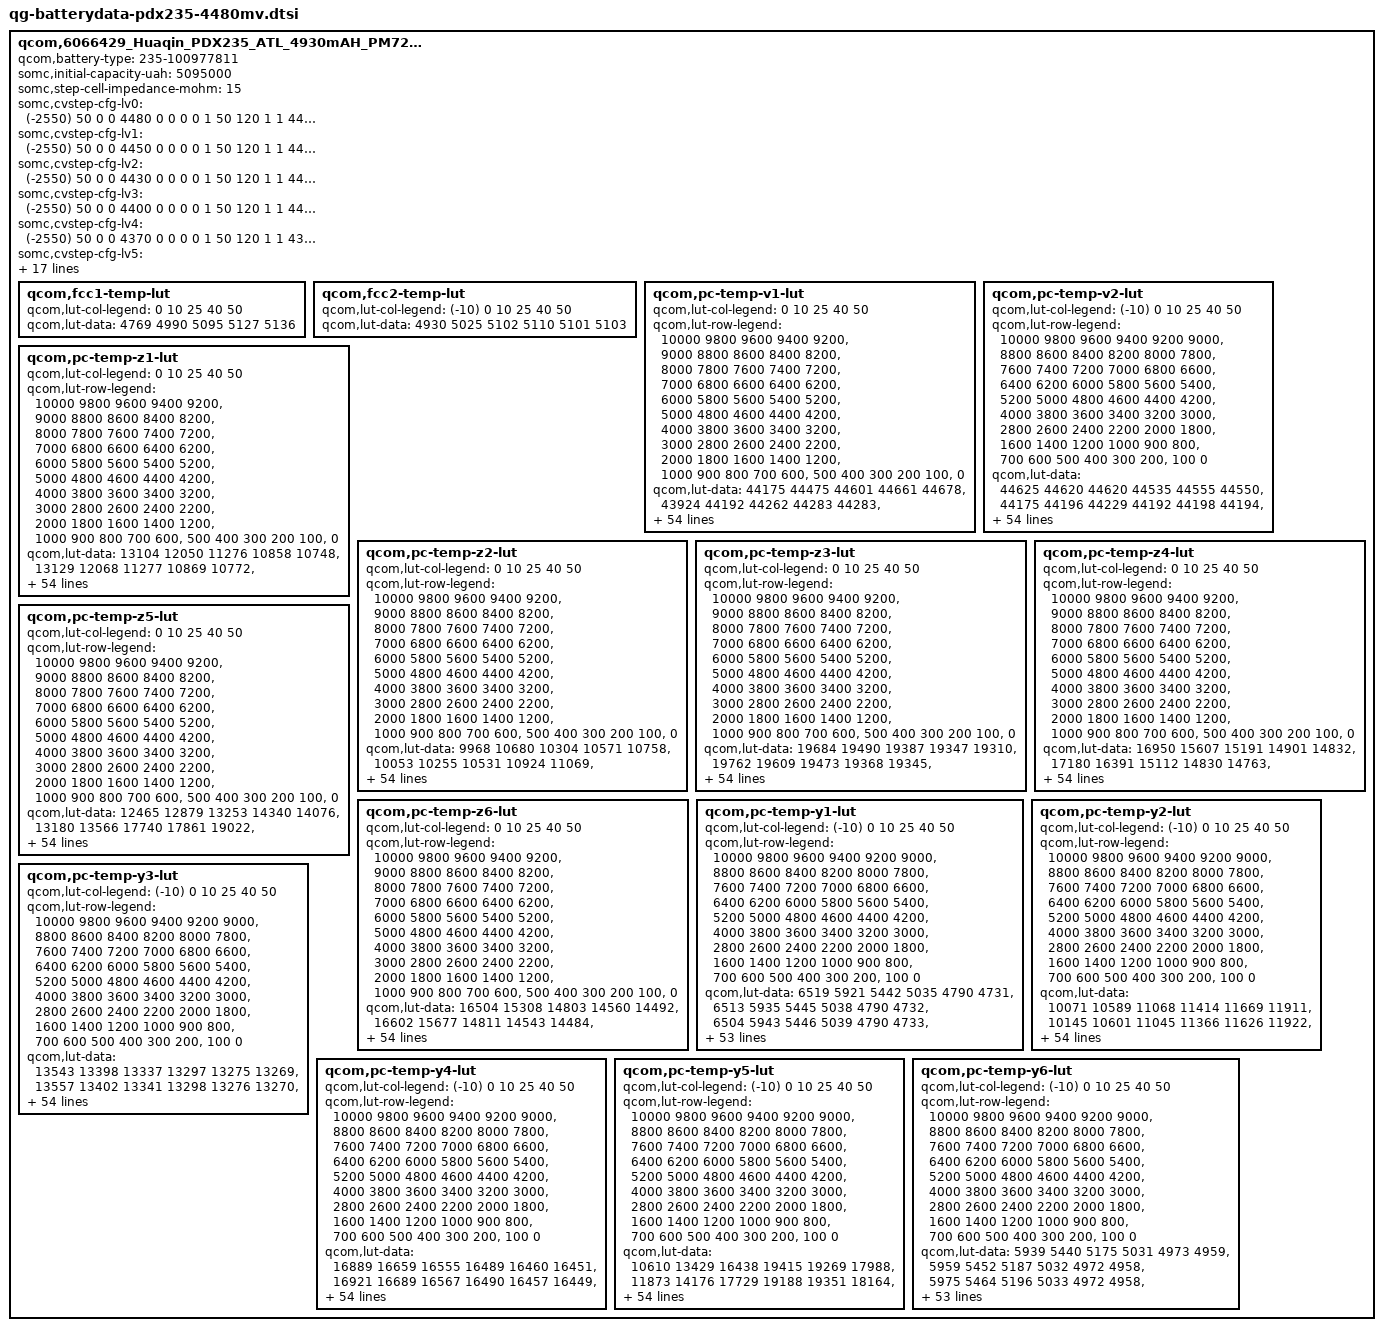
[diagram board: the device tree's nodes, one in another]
/* Copyright (c) 2018, The Linux Foundation. All rights reserved.
 *
 * This program is free software; you can redistribute it and/or modify
 * it under the terms of the GNU General Public License version 2 and
 * only version 2 as published by the Free Software Foundation.
 *
 * This program is distributed in the hope that it will be useful,
 * but WITHOUT ANY WARRANTY; without even the implied warranty of
 * MERCHANTABILITY or FITNESS FOR A PARTICULAR PURPOSE.  See the
 * GNU General Public License for more details.
 */

qcom,6066429_Huaqin_PDX235_ATL_4930mAH_PM7250B {
	qcom,battery-type = "235-100977811";
	somc,initial-capacity-uah = <5095000>;
	somc,step-cell-impedance-mohm = <15>;
	somc,cvstep-cfg-lv0 = <
		(-2550) 50 0 0 4480    0    0    0   0 1
		   50  120 1 1 4400  950  738  950   0 2
		   50  120 1 2 4480  700    0    0 246 2
		  120  150 2 1 4150 2450 1968 2450   0 3
		  120  150 2 2 4250 1950 1476 1950   0 3
		  120  150 2 3 4350 1450  984 1450   0 3
		  120  150 2 4 4480  950    0    0 246 3
		  150  200 3 1 4150 2950 2460 2950   0 3
		  150  200 3 2 4250 2450 1968 2450   0 3
		  150  200 3 3 4350 1950 1476 1950   0 3
		  150  200 3 4 4480 1450    0    0 246 3
		  200  350 4 1 4250 5000 3788 5000   0 3
		  200  350 4 2 4300 3750 2460 3750   0 3
		  200  350 4 3 4400 2450 1722 2450   0 3
		  200  350 4 4 4480 1700    0    0 246 3
		  350  450 5 1 4250 5000 3788 5000   0 3
		  350  450 5 2 4300 3750 2460 3750   0 3
		  350  450 5 3 4400 2450 1722 2450   0 3
		  350  450 5 4 4480 1700    0    0 394 3
		  450  550 6 1 4200 1450    0    0 394 4
		  550 2550 7 1 4200    0    0    0   0 5
		    0    0 0 0    0    0    0    0   0 0
	>;

	somc,cvstep-cfg-lv1 = <
		(-2550) 50 0 0 4450    0    0    0   0 1
		   50  120 1 1 4400  950  738  950   0 2
		   50  120 1 2 4450  700    0    0 246 2
		  120  150 2 1 4150 2450 1968 2450   0 3
		  120  150 2 2 4250 1950 1476 1950   0 3
		  120  150 2 3 4350 1450  984 1450   0 3
		  120  150 2 4 4450  950    0    0 246 3
		  150  200 3 1 4150 2700 2214 2700   0 3
		  150  200 3 2 4250 2200 1968 2200   0 3
		  150  200 3 3 4350 1950 1476 1950   0 3
		  150  200 3 4 4450 1450    0    0 246 3
		  200  350 4 1 4200 4650 3444 4650   0 3
		  200  350 4 2 4250 3400 2214 3400   0 3
		  200  350 4 3 4350 2200 1476 2200   0 3
		  200  350 4 4 4450 1450    0    0 246 3
		  350  450 5 1 4200 4650 3444 4650   0 3
		  350  450 5 2 4250 3400 2214 3400   0 3
		  350  450 5 3 4350 2200 1476 2200   0 3
		  350  450 5 4 4450 1450    0    0 394 3
		  450  550 6 1 4200 1450    0    0 394 4
		  550 2550 7 1 4200    0    0    0   0 5
		    0    0 0 0    0    0    0    0   0 0
	>;

	somc,cvstep-cfg-lv2 = <
		(-2550) 50 0 0 4430    0    0    0   0 1
		   50  120 1 1 4400  950  738  950   0 2
		   50  120 1 2 4430  700    0    0 246 2
		  120  150 2 1 4150 2200 1722 2200   0 3
		  120  150 2 2 4250 1700 1476 1700   0 3
		  120  150 2 3 4350 1450  984 1450   0 3
		  120  150 2 4 4430  950    0    0 246 3
		  150  200 3 1 4150 2700 2214 2700   0 3
		  150  200 3 2 4250 2200 1968 2200   0 3
		  150  200 3 3 4350 1950 1230 1950   0 3
		  150  200 3 4 4430 1200    0    0 246 3
		  200  350 4 1 4200 4400 3444 4400   0 3
		  200  350 4 2 4250 3400 2214 3400   0 3
		  200  350 4 3 4350 2200 1476 2200   0 3
		  200  350 4 4 4430 1450    0    0 246 3
		  350  450 5 1 4200 4400 3444 4400   0 3
		  350  450 5 2 4250 3400 2214 3400   0 3
		  350  450 5 3 4350 2200 1476 2200   0 3
		  350  450 5 4 4430 1450    0    0 394 3
		  450  550 6 1 4200 1450    0    0 394 4
		  550 2550 7 1 4200    0    0    0   0 5
		    0    0 0 0    0    0    0    0   0 0
	>;

	somc,cvstep-cfg-lv3 = <
		(-2550) 50 0 0 4400    0    0    0   0 1
		   50  120 1 1 4400  950    0    0 246 2
		  120  150 2 1 4150 1950 1476 1950   0 3
		  120  150 2 2 4250 1450  984 1450   0 3
		  120  150 2 3 4400  950    0    0 246 3
		  150  200 3 1 4100 2450 1968 2450   0 3
		  150  200 3 2 4200 1950 1722 1950   0 3
		  150  200 3 3 4300 1700  984 1700   0 3
		  150  200 3 4 4400  950    0    0 246 3
		  200  350 4 1 4150 3900 2952 3900   0 3
		  200  350 4 2 4200 2950 1722 2950   0 3
		  200  350 4 3 4300 1700 1230 1700   0 3
		  200  350 4 4 4400 1200    0    0 246 3
		  350  450 5 1 4150 3900 2952 3900   0 3
		  350  450 5 2 4200 2950 1722 2950   0 3
		  350  450 5 3 4300 1700 1230 1700   0 3
		  350  450 5 4 4400 1200    0    0 394 3
		  450  550 6 1 4200 1450    0    0 394 4
		  550 2550 7 1 4200    0    0    0   0 5
		    0    0 0 0    0    0    0    0   0 0
	>;

	somc,cvstep-cfg-lv4 = <
		(-2550) 50 0 0 4370    0    0    0   0 1
		   50  120 1 1 4370  950    0    0 246 2
		  120  150 2 1 4150 1950 1476 1950   0 3
		  120  150 2 2 4250 1450  984 1450   0 3
		  120  150 2 3 4370  950    0    0 246 3
		  150  200 3 1 4100 2450 1968 2450   0 3
		  150  200 3 2 4200 1950 1722 1950   0 3
		  150  200 3 3 4300 1700  984 1700   0 3
		  150  200 3 4 4370  950    0    0 246 3
		  200  350 4 1 4150 3900 2952 3900   0 3
		  200  350 4 2 4200 2950 1722 2950   0 3
		  200  350 4 3 4300 1700 1230 1700   0 3
		  200  350 4 4 4370 1200    0    0 246 3
		  350  450 5 1 4150 3900 2952 3900   0 3
		  350  450 5 2 4200 2950 1722 2950   0 3
		  350  450 5 3 4300 1700 1230 1700   0 3
		  350  450 5 4 4370 1200    0    0 394 3
		  450  550 6 1 4200 1450    0    0 394 4
		  550 2550 7 1 4200    0    0    0   0 5
		    0    0 0 0    0    0    0    0   0 0
	>;

	somc,cvstep-cfg-lv5 = <
		(-2550) 50 0 0 4350    0    0    0   0 1
		   50  120 1 1 4350  950    0    0 246 2
		  120  150 2 1 4150 1950 1476 1950   0 3
		  120  150 2 2 4250 1450  984 1450   0 3
		  120  150 2 3 4350  950    0    0 246 3
		  150  200 3 1 4100 2450 1968 2450   0 3
		  150  200 3 2 4200 1950 1722 1950   0 3
		  150  200 3 3 4300 1700  984 1700   0 3
		  150  200 3 4 4350  950    0    0 246 3
		  200  350 4 1 4150 3900 2952 3900   0 3
		  200  350 4 2 4200 2950 1722 2950   0 3
		  200  350 4 3 4300 1700 1230 1700   0 3
		  200  350 4 4 4350 1200    0    0 246 3
		  350  450 5 1 4150 3900 2952 3900   0 3
		  350  450 5 2 4200 2950 1722 2950   0 3
		  350  450 5 3 4300 1700 1230 1700   0 3
		  350  450 5 4 4350 1200    0    0 394 3
		  450  550 6 1 4200 1450    0    0 394 4
		  550 2550 7 1 4200    0    0    0   0 5
		    0    0 0 0    0    0    0    0   0 0
	>;

    /* 6066429_Huaqin_PDX235_ATL_4930mAH_PM7250B_averaged_MasterSlave_Aug29th2022 */
    qcom,max-voltage-uv = <4480000>;
    qcom,fg-cc-cv-threshold-uv = <4470000>;
    qcom,fastchg-current-ma = <4000>;
    qcom,batt-id-kohm = <15>;
    qcom,battery-beta = <4250>;
    qcom,battery-therm-kohm = <100>;
    /* qcom,battery-type = "6066429_Huaqin_PDX235_ATL_4930mAH_PM7250B_averaged_MasterSlave_Aug29th2022"; */
    qcom,qg-batt-profile-ver = <100>;

	qcom,jeita-fcc-ranges = <50  120  950000
				121 150  2450000
				151 200  2950000
				201 350  4000000
				351 450  4000000
				451 550  1450000>;

	qcom,jeita-fv-ranges = <0   100  4480000
				101 200  4480000
				201 420  4480000
				421 434  4480000
				435 450  4480000
				451 550  4150000>;

	qcom,step-chg-ranges = <3500000  4150000  4000000
				4150001  4300000  3750000
				4300001  4400000  2450000
				4400001  4480000  1700000>;
	qcom,ocv-based-step-chg;

	/* COOL = 12 degc, WARM = 45 degC */
	qcom,jeita-soft-thresholds = <0x4A2A 0x20b8>;
	/* COLD = 5 degC, HOT = 55 degC*/
	qcom,jeita-hard-thresholds = <0x5314 0x181d>;

	qcom,fcc1-temp-lut {
		qcom,lut-col-legend = <0 10 25 40 50>;
		qcom,lut-data = <4769 4990 5095 5127 5136>;
	};

	qcom,fcc2-temp-lut {
		qcom,lut-col-legend = <(-10) 0 10 25 40 50>;
		qcom,lut-data = <4930 5025 5102 5110 5101 5103>;
	};

	qcom,pc-temp-v1-lut {
		qcom,lut-col-legend = <0 10 25 40 50>;
		qcom,lut-row-legend = <10000 9800 9600 9400 9200>,
			<9000 8800 8600 8400 8200>,
			<8000 7800 7600 7400 7200>,
			<7000 6800 6600 6400 6200>,
			<6000 5800 5600 5400 5200>,
			<5000 4800 4600 4400 4200>,
			<4000 3800 3600 3400 3200>,
			<3000 2800 2600 2400 2200>,
			<2000 1800 1600 1400 1200>,
			<1000 900 800 700 600>,
			<500 400 300 200 100>,
			<0>;
		qcom,lut-data = <44175 44475 44601 44661 44678>,
			<43924 44192 44262 44283 44283>,
			<43681 43959 44015 44015 44009>,
			<43443 43740 43796 43792 43783>,
			<43204 43513 43577 43578 43570>,
			<42965 43285 43346 43352 43347>,
			<42726 43049 43110 43119 43118>,
			<42487 42805 42867 42881 42883>,
			<42249 42557 42617 42635 42641>,
			<42015 42310 42368 42387 42394>,
			<41787 42064 42119 42140 42148>,
			<41564 41824 41873 41895 41902>,
			<41346 41591 41632 41654 41660>,
			<41134 41362 41395 41415 41424>,
			<40928 41140 41168 41184 41195>,
			<40727 40923 40953 40962 40970>,
			<40533 40714 40744 40748 40751>,
			<40349 40511 40538 40542 40544>,
			<40171 40319 40339 40344 40346>,
			<40000 40145 40151 40155 40157>,
			<39838 39980 39976 39985 39984>,
			<39683 39809 39801 39808 39806>,
			<39535 39636 39625 39580 39587>,
			<39394 39464 39443 39325 39343>,
			<39259 39293 39228 39121 39141>,
			<39129 39124 38974 38955 38973>,
			<39004 38952 38795 38817 38830>,
			<38887 38774 38693 38706 38711>,
			<38774 38638 38614 38610 38607>,
			<38670 38545 38540 38515 38505>,
			<38581 38471 38473 38424 38408>,
			<38502 38408 38409 38342 38321>,
			<38433 38355 38350 38268 38244>,
			<38372 38305 38293 38201 38175>,
			<38318 38260 38240 38142 38111>,
			<38271 38218 38189 38090 38053>,
			<38230 38178 38139 38035 37988>,
			<38187 38141 38093 37980 37916>,
			<38136 38092 38036 37916 37838>,
			<38079 38017 37948 37831 37754>,
			<38004 37923 37839 37728 37660>,
			<37894 37808 37724 37614 37548>,
			<37764 37667 37593 37481 37412>,
			<37606 37504 37427 37319 37251>,
			<37450 37331 37260 37156 37090>,
			<37302 37193 37140 37047 36983>,
			<37240 37149 37108 37019 36960>,
			<37186 37112 37086 37004 36944>,
			<37141 37090 37063 36988 36929>,
			<37104 37059 37042 36960 36899>,
			<37061 36975 36918 36805 36722>,
			<36962 36626 36538 36409 36318>,
			<36610 36061 35984 35847 35752>,
			<36018 35271 35223 35079 34985>,
			<34997 33940 34056 33899 33798>,
			<30000 30000 30000 30000 30000>;
	};

	qcom,pc-temp-v2-lut {
		qcom,lut-col-legend = <(-10) 0 10 25 40 50>;
		qcom,lut-row-legend = <10000 9800 9600 9400 9200 9000>,
			<8800 8600 8400 8200 8000 7800>,
			<7600 7400 7200 7000 6800 6600>,
			<6400 6200 6000 5800 5600 5400>,
			<5200 5000 4800 4600 4400 4200>,
			<4000 3800 3600 3400 3200 3000>,
			<2800 2600 2400 2200 2000 1800>,
			<1600 1400 1200 1000 900 800>,
			<700 600 500 400 300 200>,
			<100 0>;
		qcom,lut-data = <44625 44620 44620 44535 44555 44550>,
			<44175 44196 44229 44192 44198 44194>,
			<43794 43836 43894 43890 43886 43883>,
			<43502 43560 43631 43640 43628 43625>,
			<43277 43347 43422 43432 43416 43410>,
			<43058 43132 43206 43217 43199 43192>,
			<42819 42895 42967 42983 42965 42959>,
			<42576 42652 42723 42743 42726 42722>,
			<42331 42408 42477 42499 42484 42480>,
			<42084 42162 42229 42250 42237 42234>,
			<41836 41919 41985 42005 41992 41991>,
			<41589 41682 41745 41763 41750 41750>,
			<41341 41448 41509 41526 41512 41513>,
			<41095 41214 41277 41291 41277 41281>,
			<40852 40982 41049 41062 41049 41054>,
			<40609 40746 40826 40841 40829 40833>,
			<40367 40502 40609 40627 40616 40619>,
			<40124 40259 40385 40422 40411 40413>,
			<39874 40020 40145 40233 40216 40219>,
			<39612 39786 39902 40042 40026 40030>,
			<39381 39568 39669 39810 39840 39847>,
			<39203 39366 39442 39548 39655 39668>,
			<39046 39177 39238 39312 39450 39466>,
			<38869 38998 39053 39103 39193 39211>,
			<38674 38831 38886 38920 38958 38977>,
			<38501 38679 38734 38768 38799 38815>,
			<38365 38541 38595 38637 38672 38684>,
			<38249 38409 38468 38518 38556 38567>,
			<38156 38270 38353 38410 38450 38461>,
			<38079 38138 38245 38310 38352 38364>,
			<38009 38038 38146 38218 38264 38273>,
			<37940 37959 38053 38132 38182 38189>,
			<37874 37891 37966 38053 38105 38113>,
			<37808 37833 37883 37980 38035 38045>,
			<37742 37780 37813 37906 37961 37969>,
			<37674 37724 37760 37828 37885 37880>,
			<37604 37665 37711 37752 37803 37784>,
			<37532 37599 37659 37678 37708 37677>,
			<37458 37522 37603 37605 37603 37563>,
			<37383 37438 37536 37526 37507 37461>,
			<37308 37349 37450 37442 37425 37376>,
			<37234 37251 37347 37336 37328 37276>,
			<37158 37139 37221 37204 37208 37154>,
			<37077 37026 37061 37055 37076 37022>,
			<36997 36915 36887 36901 36912 36862>,
			<36908 36803 36780 36859 36864 36818>,
			<36853 36749 36738 36838 36856 36808>,
			<36793 36700 36695 36817 36842 36796>,
			<36727 36646 36636 36773 36817 36771>,
			<36656 36589 36533 36641 36765 36712>,
			<36566 36500 36320 36280 36566 36501>,
			<36445 36300 35875 35687 36096 36021>,
			<36282 35812 35083 34878 35461 35394>,
			<36016 34859 33953 33558 34579 34515>,
			<35414 33802 32556 32070 33241 33253>,
			<34406 32517 29740 30304 29740 29838>;
	};

	qcom,pc-temp-z1-lut {
		qcom,lut-col-legend = <0 10 25 40 50>;
		qcom,lut-row-legend = <10000 9800 9600 9400 9200>,
			<9000 8800 8600 8400 8200>,
			<8000 7800 7600 7400 7200>,
			<7000 6800 6600 6400 6200>,
			<6000 5800 5600 5400 5200>,
			<5000 4800 4600 4400 4200>,
			<4000 3800 3600 3400 3200>,
			<3000 2800 2600 2400 2200>,
			<2000 1800 1600 1400 1200>,
			<1000 900 800 700 600>,
			<500 400 300 200 100>,
			<0>;
		qcom,lut-data = <13104 12050 11276 10858 10748>,
			<13129 12068 11277 10869 10772>,
			<13117 12053 11263 10863 10767>,
			<13091 12032 11255 10858 10766>,
			<13071 12017 11247 10854 10766>,
			<13055 12002 11236 10851 10766>,
			<13044 11985 11225 10848 10766>,
			<13012 11958 11217 10847 10765>,
			<12962 11930 11210 10845 10764>,
			<12932 11905 11206 10844 10763>,
			<12888 11881 11206 10844 10763>,
			<12831 11866 11207 10844 10763>,
			<12785 11854 11208 10844 10763>,
			<12739 11848 11211 10844 10763>,
			<12703 11851 11214 10844 10764>,
			<12677 11855 11216 10845 10764>,
			<12654 11859 11219 10847 10765>,
			<12626 11862 11221 10848 10765>,
			<12587 11868 11224 10848 10766>,
			<12559 11880 11228 10850 10768>,
			<12548 11895 11232 10852 10769>,
			<12542 11896 11236 10854 10771>,
			<12545 11889 11242 10856 10772>,
			<12558 11885 11247 10857 10773>,
			<12573 11898 11253 10859 10775>,
			<12592 11916 11258 10861 10777>,
			<12618 11918 11263 10864 10779>,
			<12628 11913 11269 10868 10782>,
			<12626 11910 11275 10871 10784>,
			<12624 11916 11280 10875 10786>,
			<12621 11926 11285 10878 10789>,
			<12608 11934 11291 10881 10791>,
			<12602 11941 11297 10885 10794>,
			<12622 11947 11303 10888 10797>,
			<12653 11954 11311 10892 10799>,
			<12664 11962 11319 10897 10802>,
			<12663 11973 11328 10901 10804>,
			<12663 11988 11339 10906 10807>,
			<12675 12005 11350 10910 10810>,
			<12699 12023 11361 10914 10812>,
			<12731 12045 11372 10917 10814>,
			<12793 12077 11383 10921 10817>,
			<12819 12108 11394 10925 10819>,
			<12804 12120 11404 10928 10821>,
			<12851 12125 11416 10932 10823>,
			<12823 12120 11426 10936 10825>,
			<12834 12121 11423 10936 10825>,
			<12834 12125 11425 10936 10826>,
			<12804 12148 11430 10938 10827>,
			<12807 12132 11444 10942 10829>,
			<12850 12148 11456 10950 10834>,
			<12823 12208 11474 10958 10841>,
			<12874 12206 11507 10972 10852>,
			<12886 12242 11546 10993 10867>,
			<12886 12242 11546 10993 10867>,
			<12886 12242 11546 10993 10867>;
	};

	qcom,pc-temp-z2-lut {
		qcom,lut-col-legend = <0 10 25 40 50>;
		qcom,lut-row-legend = <10000 9800 9600 9400 9200>,
			<9000 8800 8600 8400 8200>,
			<8000 7800 7600 7400 7200>,
			<7000 6800 6600 6400 6200>,
			<6000 5800 5600 5400 5200>,
			<5000 4800 4600 4400 4200>,
			<4000 3800 3600 3400 3200>,
			<3000 2800 2600 2400 2200>,
			<2000 1800 1600 1400 1200>,
			<1000 900 800 700 600>,
			<500 400 300 200 100>,
			<0>;
		qcom,lut-data = <9968 10680 10304 10571 10758>,
			<10053 10255 10531 10924 11069>,
			<10125 10332 10609 10987 11222>,
			<10177 10378 10573 10943 11186>,
			<10185 10387 10533 10870 11106>,
			<10180 10391 10511 10825 11068>,
			<10175 10391 10495 10790 11045>,
			<10176 10384 10491 10781 11033>,
			<10177 10375 10491 10806 11025>,
			<10177 10369 10491 10837 11021>,
			<10173 10362 10482 10855 11033>,
			<10168 10359 10473 10869 11065>,
			<10169 10358 10473 10888 11069>,
			<10173 10357 10476 10920 11017>,
			<10178 10348 10503 10936 10978>,
			<10185 10334 10835 10879 10988>,
			<10194 10330 11137 10799 11011>,
			<10204 10332 10983 10806 11042>,
			<10217 10337 10644 10862 11089>,
			<10228 10565 10559 10883 11116>,
			<10235 10912 10574 10869 11124>,
			<10241 10908 10592 10854 11132>,
			<10244 10586 10610 10977 11227>,
			<10248 10397 10628 11244 11434>,
			<10255 10415 10648 11273 11475>,
			<10263 10447 10668 11003 11314>,
			<10273 10473 10676 10826 11197>,
			<10285 10499 10660 10916 11216>,
			<10299 10509 10644 11050 11247>,
			<10314 10509 10644 11085 11241>,
			<10328 10509 10650 11100 11187>,
			<10342 10510 10656 11097 11124>,
			<10356 10511 10662 11021 11027>,
			<10369 10513 10669 10948 10951>,
			<10383 10521 10675 10967 10979>,
			<10395 10529 10680 11024 11074>,
			<10407 10530 10680 11065 11173>,
			<10416 10530 10676 11093 11315>,
			<10419 10532 10673 11120 11411>,
			<10423 10540 10685 11151 11402>,
			<10430 10551 10701 11177 11363>,
			<10447 10556 10698 11174 11354>,
			<10478 10560 10687 11157 11347>,
			<10540 10569 10687 11163 11350>,
			<10274 10649 10709 11179 11355>,
			<10035 10834 10779 11111 11359>,
			<9855 10860 10757 11100 11342>,
			<9882 10875 10746 11077 11327>,
			<9867 11042 10743 11056 11308>,
			<9823 11067 10799 11075 11376>,
			<9783 11100 10766 11278 11269>,
			<9683 10857 10794 11143 11135>,
			<9595 10703 10739 10973 10921>,
			<9684 10485 10650 10829 10893>,
			<9684 10485 10650 10829 10893>,
			<9684 10485 10650 10829 10893>;
	};

	qcom,pc-temp-z3-lut {
		qcom,lut-col-legend = <0 10 25 40 50>;
		qcom,lut-row-legend = <10000 9800 9600 9400 9200>,
			<9000 8800 8600 8400 8200>,
			<8000 7800 7600 7400 7200>,
			<7000 6800 6600 6400 6200>,
			<6000 5800 5600 5400 5200>,
			<5000 4800 4600 4400 4200>,
			<4000 3800 3600 3400 3200>,
			<3000 2800 2600 2400 2200>,
			<2000 1800 1600 1400 1200>,
			<1000 900 800 700 600>,
			<500 400 300 200 100>,
			<0>;
		qcom,lut-data = <19684 19490 19387 19347 19310>,
			<19762 19609 19473 19368 19345>,
			<19780 19665 19526 19415 19374>,
			<19791 19691 19535 19418 19380>,
			<19797 19685 19538 19420 19381>,
			<19802 19666 19537 19421 19381>,
			<19805 19647 19534 19422 19380>,
			<19809 19629 19529 19422 19377>,
			<19814 19616 19520 19412 19370>,
			<19815 19611 19509 19399 19362>,
			<19813 19607 19496 19389 19358>,
			<19809 19602 19484 19381 19355>,
			<19804 19595 19476 19376 19350>,
			<19795 19589 19469 19373 19340>,
			<19786 19588 19468 19369 19332>,
			<19776 19588 19480 19359 19330>,
			<19765 19587 19491 19348 19328>,
			<19753 19583 19478 19345 19324>,
			<19741 19581 19449 19343 19319>,
			<19732 19595 19437 19342 19315>,
			<19728 19617 19433 19340 19315>,
			<19725 19614 19431 19339 19315>,
			<19725 19582 19434 19348 19321>,
			<19725 19563 19440 19368 19333>,
			<19726 19567 19446 19371 19335>,
			<19727 19574 19454 19356 19321>,
			<19729 19580 19457 19344 19311>,
			<19730 19588 19451 19341 19314>,
			<19732 19591 19445 19339 19320>,
			<19733 19587 19441 19344 19329>,
			<19732 19581 19439 19362 19343>,
			<19728 19575 19438 19370 19349>,
			<19722 19570 19439 19369 19342>,
			<19718 19566 19441 19367 19334>,
			<19712 19563 19442 19364 19329>,
			<19706 19560 19444 19358 19325>,
			<19699 19556 19444 19354 19324>,
			<19690 19551 19441 19351 19325>,
			<19679 19547 19438 19349 19325>,
			<19665 19544 19437 19348 19324>,
			<19652 19541 19435 19348 19321>,
			<19639 19536 19433 19346 19320>,
			<19623 19528 19429 19344 19319>,
			<19595 19520 19426 19343 19318>,
			<19402 19499 19417 19339 19316>,
			<19330 19454 19403 19332 19313>,
			<19303 19442 19400 19332 19311>,
			<19299 19432 19396 19328 19309>,
			<19296 19330 19395 19327 19308>,
			<19293 19306 19362 19325 19303>,
			<19291 19305 19387 19317 19316>,
			<19269 19334 19384 19326 19320>,
			<19276 19340 19380 19332 19330>,
			<19314 19347 19382 19341 19326>,
			<19314 19347 19382 19341 19326>,
			<19314 19347 19382 19341 19326>;
	};

	qcom,pc-temp-z4-lut {
		qcom,lut-col-legend = <0 10 25 40 50>;
		qcom,lut-row-legend = <10000 9800 9600 9400 9200>,
			<9000 8800 8600 8400 8200>,
			<8000 7800 7600 7400 7200>,
			<7000 6800 6600 6400 6200>,
			<6000 5800 5600 5400 5200>,
			<5000 4800 4600 4400 4200>,
			<4000 3800 3600 3400 3200>,
			<3000 2800 2600 2400 2200>,
			<2000 1800 1600 1400 1200>,
			<1000 900 800 700 600>,
			<500 400 300 200 100>,
			<0>;
		qcom,lut-data = <16950 15607 15191 14901 14832>,
			<17180 16391 15112 14830 14763>,
			<16965 16091 15358 14932 14822>,
			<16576 15723 15213 14900 14813>,
			<16271 15530 15058 14843 14781>,
			<16009 15384 14980 14805 14757>,
			<15790 15271 14921 14774 14733>,
			<15620 15182 14873 14754 14721>,
			<15479 15109 14834 14741 14717>,
			<15367 15044 14805 14732 14713>,
			<15274 14988 14786 14725 14707>,
			<15199 14939 14772 14720 14698>,
			<15137 14895 14760 14712 14694>,
			<15084 14860 14750 14701 14692>,
			<15041 14836 14734 14694 14689>,
			<15005 14818 14695 14693 14683>,
			<14976 14803 14665 14693 14674>,
			<14950 14793 14677 14690 14668>,
			<14927 14780 14703 14682 14665>,
			<14908 14738 14710 14675 14661>,
			<14894 14689 14706 14670 14655>,
			<14883 14688 14703 14667 14651>,
			<14873 14727 14704 14679 14663>,
			<14863 14753 14707 14711 14698>,
			<14855 14757 14726 14741 14728>,
			<14847 14760 14790 14774 14759>,
			<14841 14772 14820 14790 14774>,
			<14837 14799 14815 14785 14765>,
			<14836 14813 14807 14773 14744>,
			<14835 14812 14796 14753 14720>,
			<14833 14810 14782 14719 14690>,
			<14832 14805 14768 14696 14672>,
			<14830 14796 14753 14683 14665>,
			<14825 14786 14740 14676 14661>,
			<14820 14778 14729 14674 14660>,
			<14813 14769 14721 14672 14658>,
			<14805 14761 14716 14673 14659>,
			<14796 14753 14712 14677 14670>,
			<14786 14746 14711 14682 14678>,
			<14775 14740 14715 14688 14679>,
			<14766 14733 14720 14693 14680>,
			<14757 14727 14716 14690 14678>,
			<14752 14720 14701 14680 14669>,
			<14749 14710 14696 14679 14670>,
			<14863 14692 14686 14677 14669>,
			<14919 14683 14663 14660 14655>,
			<14944 14691 14658 14652 14648>,
			<14944 14695 14650 14640 14634>,
			<14943 14805 14642 14626 14620>,
			<14946 14826 14671 14624 14620>,
			<14940 14824 14654 14652 14625>,
			<14956 14807 14672 14651 14627>,
			<14965 14810 14684 14646 14619>,
			<14953 14817 14689 14638 14622>,
			<14953 14817 14689 14638 14622>,
			<14953 14817 14689 14638 14622>;
	};

	qcom,pc-temp-z5-lut {
		qcom,lut-col-legend = <0 10 25 40 50>;
		qcom,lut-row-legend = <10000 9800 9600 9400 9200>,
			<9000 8800 8600 8400 8200>,
			<8000 7800 7600 7400 7200>,
			<7000 6800 6600 6400 6200>,
			<6000 5800 5600 5400 5200>,
			<5000 4800 4600 4400 4200>,
			<4000 3800 3600 3400 3200>,
			<3000 2800 2600 2400 2200>,
			<2000 1800 1600 1400 1200>,
			<1000 900 800 700 600>,
			<500 400 300 200 100>,
			<0>;
		qcom,lut-data = <12465 12879 13253 14340 14076>,
			<13180 13566 17740 17861 19022>,
			<13916 14352 16077 18502 19815>,
			<14644 14988 16656 18712 20011>,
			<15331 15308 17374 19179 20358>,
			<15990 15525 17895 19833 20882>,
			<16644 15762 18390 20776 21766>,
			<17325 16008 18897 21112 22124>,
			<18018 16299 19424 21018 21491>,
			<18657 16747 19850 20875 20813>,
			<19244 17366 20114 20596 20945>,
			<19756 18014 20367 20185 21360>,
			<20195 18717 20746 20209 21350>,
			<20625 19446 21303 20993 20199>,
			<21005 20180 22547 21498 19347>,
			<21377 20960 28174 20611 19828>,
			<21683 21770 32972 19376 20591>,
			<21873 22543 30726 19434 20642>,
			<22169 23772 25740 20311 20370>,
			<22509 29376 24545 21231 20262>,
			<22943 36652 25262 21919 21249>,
			<23519 36907 26488 22982 23174>,
			<24197 32057 29562 31268 27446>,
			<25087 29224 34467 46806 34183>,
			<26189 32378 39856 48804 34949>,
			<27576 38004 46372 35378 25848>,
			<29300 42675 48755 24510 18756>,
			<31132 47405 43065 21304 17960>,
			<33456 49295 35723 19470 17552>,
			<35418 46660 32419 19948 18581>,
			<36075 42655 30169 22842 23264>,
			<36444 40154 29693 26083 26466>,
			<36560 38134 30403 29803 27808>,
			<36488 37220 31609 33132 28873>,
			<36332 36990 34216 35182 30350>,
			<36060 36835 37666 36689 32588>,
			<35427 36440 38948 36916 33395>,
			<34633 35675 39574 36188 33515>,
			<33505 35413 39805 35039 33439>,
			<32051 36520 39484 32552 30912>,
			<31141 37674 38853 29697 26995>,
			<30050 36678 37717 28944 26058>,
			<28824 34379 35787 28697 26066>,
			<26255 33827 34827 27206 24417>,
			<15740 33708 34660 25939 22874>,
			<12705 29368 35146 26609 24342>,
			<12216 24438 33532 27990 24361>,
			<12151 21652 31113 27630 26481>,
			<12078 13806 31212 31189 32682>,
			<11935 12446 19365 31262 29587>,
			<11882 12444 27054 20404 27285>,
			<11645 13289 21562 19507 26375>,
			<11715 13293 18918 20620 33364>,
			<12438 13303 18119 23110 28114>,
			<12438 13303 18119 23110 28114>,
			<12438 13303 18119 23110 28114>;
	};

	qcom,pc-temp-z6-lut {
		qcom,lut-col-legend = <0 10 25 40 50>;
		qcom,lut-row-legend = <10000 9800 9600 9400 9200>,
			<9000 8800 8600 8400 8200>,
			<8000 7800 7600 7400 7200>,
			<7000 6800 6600 6400 6200>,
			<6000 5800 5600 5400 5200>,
			<5000 4800 4600 4400 4200>,
			<4000 3800 3600 3400 3200>,
			<3000 2800 2600 2400 2200>,
			<2000 1800 1600 1400 1200>,
			<1000 900 800 700 600>,
			<500 400 300 200 100>,
			<0>;
		qcom,lut-data = <16504 15308 14803 14560 14492>,
			<16602 15677 14811 14543 14484>,
			<16494 15561 14937 14610 14524>,
			<16298 15409 14876 14596 14522>,
			<16141 15310 14809 14573 14510>,
			<16003 15226 14771 14557 14500>,
			<15885 15156 14741 14546 14490>,
			<15790 15097 14715 14534 14482>,
			<15709 15047 14691 14523 14476>,
			<15639 15007 14672 14513 14471>,
			<15578 14972 14656 14505 14466>,
			<15524 14942 14644 14498 14461>,
			<15475 14913 14635 14491 14455>,
			<15431 14893 14627 14485 14449>,
			<15392 14882 14620 14480 14444>,
			<15355 14875 14612 14474 14439>,
			<15322 14868 14605 14468 14434>,
			<15293 14862 14601 14464 14430>,
			<15265 14856 14598 14460 14425>,
			<15248 14848 14595 14457 14422>,
			<15240 14841 14592 14454 14420>,
			<15235 14840 14590 14452 14418>,
			<15233 14841 14592 14463 14427>,
			<15233 14842 14598 14488 14449>,
			<15233 14847 14612 14501 14462>,
			<15233 14854 14644 14507 14468>,
			<15235 14865 14658 14510 14471>,
			<15237 14883 14655 14507 14468>,
			<15240 14890 14650 14501 14463>,
			<15243 14889 14644 14496 14459>,
			<15244 14888 14638 14491 14454>,
			<15244 14885 14633 14486 14449>,
			<15244 14880 14628 14481 14442>,
			<15243 14876 14625 14477 14437>,
			<15242 14874 14623 14473 14433>,
			<15241 14872 14622 14470 14430>,
			<15239 14870 14622 14470 14431>,
			<15238 14869 14621 14471 14436>,
			<15238 14868 14622 14472 14440>,
			<15239 14871 14625 14474 14440>,
			<15241 14873 14630 14477 14439>,
			<15245 14874 14628 14476 14438>,
			<15248 14874 14624 14471 14434>,
			<15250 14873 14622 14470 14434>,
			<15228 14865 14618 14468 14433>,
			<15221 14848 14603 14457 14426>,
			<15221 14846 14601 14454 14422>,
			<15221 14843 14595 14447 14415>,
			<15220 14840 14593 14441 14408>,
			<15223 14841 14591 14440 14405>,
			<15226 14849 14601 14448 14416>,
			<15237 14866 14613 14455 14420>,
			<15259 14883 14622 14459 14424>,
			<15289 14908 14634 14464 14427>,
			<15289 14908 14634 14464 14427>,
			<15289 14908 14634 14464 14427>;
	};

	qcom,pc-temp-y1-lut {
		qcom,lut-col-legend = <(-10) 0 10 25 40 50>;
		qcom,lut-row-legend = <10000 9800 9600 9400 9200 9000>,
			<8800 8600 8400 8200 8000 7800>,
			<7600 7400 7200 7000 6800 6600>,
			<6400 6200 6000 5800 5600 5400>,
			<5200 5000 4800 4600 4400 4200>,
			<4000 3800 3600 3400 3200 3000>,
			<2800 2600 2400 2200 2000 1800>,
			<1600 1400 1200 1000 900 800>,
			<700 600 500 400 300 200>,
			<100 0>;
		qcom,lut-data = <6519 5921 5442 5035 4790 4731>,
			<6513 5935 5445 5038 4790 4732>,
			<6504 5943 5446 5039 4790 4733>,
			<6494 5946 5447 5039 4790 4733>,
			<6487 5946 5446 5038 4789 4733>,
			<6487 5944 5446 5038 4788 4732>,
			<6495 5932 5443 5036 4787 4731>,
			<6502 5919 5439 5035 4785 4729>,
			<6500 5917 5438 5034 4784 4728>,
			<6483 5916 5436 5031 4782 4727>,
			<6473 5917 5433 5031 4781 4727>,
			<6479 5936 5428 5031 4780 4727>,
			<6489 5957 5424 5031 4779 4726>,
			<6497 5956 5424 5028 4779 4726>,
			<6506 5951 5426 5024 4779 4726>,
			<6510 5949 5426 5023 4779 4726>,
			<6499 5941 5421 5023 4778 4726>,
			<6484 5932 5419 5023 4777 4726>,
			<6481 5935 5424 5024 4778 4726>,
			<6481 5943 5430 5026 4778 4727>,
			<6481 5946 5432 5027 4779 4728>,
			<6492 5941 5432 5028 4780 4729>,
			<6510 5939 5434 5029 4780 4730>,
			<6512 5948 5438 5032 4781 4730>,
			<6496 5960 5441 5035 4783 4731>,
			<6484 5959 5441 5037 4784 4731>,
			<6493 5944 5441 5038 4786 4732>,
			<6509 5935 5442 5040 4787 4733>,
			<6509 5937 5446 5044 4788 4734>,
			<6489 5943 5448 5047 4790 4735>,
			<6476 5952 5449 5048 4791 4736>,
			<6480 5967 5450 5050 4794 4738>,
			<6488 5975 5452 5052 4796 4739>,
			<6488 5958 5454 5057 4798 4740>,
			<6478 5936 5456 5059 4800 4742>,
			<6471 5936 5460 5060 4802 4743>,
			<6470 5944 5462 5061 4803 4744>,
			<6469 5948 5463 5061 4804 4745>,
			<6473 5943 5464 5061 4805 4747>,
			<6487 5936 5464 5062 4806 4748>,
			<6495 5934 5461 5064 4807 4748>,
			<6488 5933 5461 5065 4808 4749>,
			<6477 5926 5466 5069 4809 4750>,
			<6466 5930 5487 5081 4812 4751>,
			<6477 5991 5489 5080 4815 4753>,
			<6509 5969 5494 5083 4816 4755>,
			<6564 6006 5498 5085 4817 4755>,
			<6549 5985 5492 5091 4819 4756>,
			<6612 5968 5488 5097 4819 4757>,
			<6666 5998 5497 5095 4820 4757>,
			<6705 6037 5518 5099 4821 4758>,
			<6831 6128 5521 5118 4826 4759>,
			<6914 6271 5593 5137 4832 4766>,
			<7069 6465 5765 5167 4842 4773>,
			<7069 6465 5765 5167 4842 4773>,
			<7069 6465 5765 5167 4842 4773>;
	};

	qcom,pc-temp-y2-lut {
		qcom,lut-col-legend = <(-10) 0 10 25 40 50>;
		qcom,lut-row-legend = <10000 9800 9600 9400 9200 9000>,
			<8800 8600 8400 8200 8000 7800>,
			<7600 7400 7200 7000 6800 6600>,
			<6400 6200 6000 5800 5600 5400>,
			<5200 5000 4800 4600 4400 4200>,
			<4000 3800 3600 3400 3200 3000>,
			<2800 2600 2400 2200 2000 1800>,
			<1600 1400 1200 1000 900 800>,
			<700 600 500 400 300 200>,
			<100 0>;
		qcom,lut-data = <10071 10589 11068 11414 11669 11911>,
			<10145 10601 11045 11366 11626 11922>,
			<10220 10630 11021 11321 11567 11887>,
			<10290 10663 10996 11277 11508 11829>,
			<10350 10690 10971 11237 11465 11768>,
			<10394 10699 10945 11199 11451 11727>,
			<10422 10699 10914 11157 11458 11672>,
			<10444 10698 10889 11127 11468 11624>,
			<10468 10702 10883 11122 11471 11611>,
			<10495 10719 10879 11122 11471 11596>,
			<10525 10738 10880 11126 11461 11583>,
			<10565 10758 10892 11139 11433 11588>,
			<10611 10782 10910 11156 11413 11603>,
			<10650 10811 10933 11171 11425 11639>,
			<10684 10847 10963 11187 11455 11690>,
			<10718 10881 10997 11208 11490 11715>,
			<10766 10910 11038 11235 11538 11731>,
			<10809 10937 11072 11267 11599 11747>,
			<10709 10960 11094 11316 11689 11777>,
			<10154 10981 11113 11356 11791 11827>,
			<9792 11002 11130 11342 11881 11936>,
			<9974 11023 11146 11294 11966 12131>,
			<10240 11047 11165 11279 11981 12188>,
			<10212 11081 11191 11311 11811 12009>,
			<9899 11117 11217 11352 11653 11848>,
			<9705 11130 11238 11381 11657 11873>,
			<9692 11130 11255 11409 11684 11939>,
			<9685 11121 11275 11434 11712 11982>,
			<9680 11102 11300 11460 11745 12010>,
			<9677 11078 11316 11479 11787 12038>,
			<9675 11061 11320 11494 11866 12071>,
			<9672 11044 11321 11506 11950 12100>,
			<9671 11021 11317 11508 11976 12143>,
			<9669 10980 11312 11508 11987 12255>,
			<9668 10918 11303 11508 11995 12292>,
			<9667 10777 11283 11505 11985 12197>,
			<9666 10451 11255 11502 11963 12104>,
			<9665 10230 11221 11503 11906 12095>,
			<9664 9943 11176 11503 11802 12090>,
			<9664 9711 11128 11497 11771 12098>,
			<9663 9688 11074 11471 11783 12168>,
			<9662 9679 11001 11434 11804 12168>,
			<9662 9673 10899 11383 11845 12059>,
			<9661 9668 10777 11344 11780 12049>,
			<9660 9665 10441 11330 11774 12043>,
			<9659 9663 9953 11231 11721 11884>,
			<9658 9661 9830 11213 11655 11900>,
			<9657 9660 9736 11193 11638 11843>,
			<9655 9658 9691 11184 11707 11755>,
			<9653 9655 9672 11145 11645 11691>,
			<9651 9652 9662 11040 11603 11696>,
			<9650 9649 9655 10908 11549 11578>,
			<9649 9648 9653 10744 11418 11445>,
			<9648 9649 9658 10452 11289 11289>,
			<9648 9649 9658 10452 11289 11289>,
			<9648 9649 9658 10452 11289 11289>;
	};

	qcom,pc-temp-y3-lut {
		qcom,lut-col-legend = <(-10) 0 10 25 40 50>;
		qcom,lut-row-legend = <10000 9800 9600 9400 9200 9000>,
			<8800 8600 8400 8200 8000 7800>,
			<7600 7400 7200 7000 6800 6600>,
			<6400 6200 6000 5800 5600 5400>,
			<5200 5000 4800 4600 4400 4200>,
			<4000 3800 3600 3400 3200 3000>,
			<2800 2600 2400 2200 2000 1800>,
			<1600 1400 1200 1000 900 800>,
			<700 600 500 400 300 200>,
			<100 0>;
		qcom,lut-data = <13543 13398 13337 13297 13275 13269>,
			<13557 13402 13341 13298 13276 13270>,
			<13570 13411 13345 13300 13277 13270>,
			<13582 13422 13350 13301 13278 13271>,
			<13590 13430 13354 13302 13279 13272>,
			<13593 13433 13356 13303 13280 13273>,
			<13591 13434 13357 13304 13281 13273>,
			<13587 13434 13357 13304 13283 13274>,
			<13582 13433 13357 13304 13284 13275>,
			<13576 13431 13357 13304 13284 13275>,
			<13568 13429 13357 13304 13285 13276>,
			<13560 13427 13357 13308 13285 13278>,
			<13550 13426 13357 13310 13285 13279>,
			<13539 13424 13356 13310 13285 13280>,
			<13527 13422 13356 13309 13284 13281>,
			<13514 13419 13355 13309 13284 13282>,
			<13502 13413 13356 13310 13287 13281>,
			<13489 13407 13356 13311 13288 13280>,
			<13471 13401 13353 13314 13287 13281>,
			<13443 13395 13348 13316 13287 13282>,
			<13428 13389 13344 13315 13287 13282>,
			<13431 13384 13339 13310 13288 13283>,
			<13436 13380 13336 13306 13288 13283>,
			<13439 13374 13333 13302 13283 13278>,
			<13441 13369 13331 13299 13278 13273>,
			<13442 13364 13329 13298 13278 13272>,
			<13443 13360 13327 13298 13277 13271>,
			<13443 13356 13326 13298 13277 13271>,
			<13448 13352 13325 13299 13277 13271>,
			<13465 13348 13324 13300 13276 13271>,
			<13488 13345 13323 13300 13277 13272>,
			<13511 13342 13322 13300 13277 13272>,
			<13538 13341 13321 13300 13278 13272>,
			<13568 13344 13321 13299 13279 13272>,
			<13605 13349 13321 13299 13279 13272>,
			<13645 13355 13322 13298 13279 13272>,
			<13691 13364 13324 13298 13279 13272>,
			<13742 13375 13326 13298 13278 13272>,
			<13798 13392 13329 13298 13276 13271>,
			<13862 13413 13331 13298 13276 13271>,
			<13929 13440 13334 13298 13276 13272>,
			<14000 13474 13336 13299 13276 13272>,
			<14073 13521 13338 13299 13277 13271>,
			<14146 13592 13339 13299 13276 13271>,
			<14236 13648 13327 13293 13274 13269>,
			<14263 13780 13343 13300 13276 13271>,
			<14350 13893 13363 13301 13279 13273>,
			<14507 14052 13398 13306 13280 13277>,
			<14816 14269 13453 13312 13282 13279>,
			<15368 14636 13563 13315 13287 13280>,
			<16466 15668 13811 13315 13286 13280>,
			<19011 19167 14572 13321 13284 13278>,
			<26802 35899 18016 13336 13286 13281>,
			<58645 65535 37023 13387 13290 13282>,
			<58645 65535 37023 13387 13290 13282>,
			<58645 65535 37023 13387 13290 13282>;
	};

	qcom,pc-temp-y4-lut {
		qcom,lut-col-legend = <(-10) 0 10 25 40 50>;
		qcom,lut-row-legend = <10000 9800 9600 9400 9200 9000>,
			<8800 8600 8400 8200 8000 7800>,
			<7600 7400 7200 7000 6800 6600>,
			<6400 6200 6000 5800 5600 5400>,
			<5200 5000 4800 4600 4400 4200>,
			<4000 3800 3600 3400 3200 3000>,
			<2800 2600 2400 2200 2000 1800>,
			<1600 1400 1200 1000 900 800>,
			<700 600 500 400 300 200>,
			<100 0>;
		qcom,lut-data = <16889 16659 16555 16489 16460 16451>,
			<16921 16689 16567 16490 16457 16449>,
			<16982 16736 16589 16492 16454 16446>,
			<17051 16785 16612 16494 16452 16442>,
			<17108 16826 16630 16496 16449 16440>,
			<17133 16845 16636 16499 16449 16439>,
			<17135 16850 16635 16502 16449 16440>,
			<17134 16852 16633 16505 16450 16440>,
			<17131 16854 16634 16510 16451 16442>,
			<17124 16855 16636 16517 16454 16445>,
			<17114 16856 16639 16522 16458 16447>,
			<17102 16860 16648 16527 16463 16450>,
			<17088 16864 16658 16533 16470 16452>,
			<17073 16863 16670 16545 16478 16454>,
			<17059 16859 16683 16563 16488 16458>,
			<17040 16852 16692 16580 16496 16464>,
			<17004 16834 16700 16598 16503 16473>,
			<16966 16810 16703 16615 16512 16483>,
			<16961 16784 16687 16635 16529 16492>,
			<16972 16755 16658 16650 16549 16503>,
			<16978 16731 16631 16634 16564 16518>,
			<16942 16712 16600 16580 16578 16538>,
			<16877 16695 16579 16538 16578 16541>,
			<16832 16679 16563 16506 16518 16496>,
			<16792 16665 16552 16488 16461 16453>,
			<16767 16652 16547 16486 16456 16448>,
			<16758 16642 16543 16486 16454 16446>,
			<16752 16629 16541 16486 16455 16446>,
			<16752 16600 16540 16490 16461 16451>,
			<16753 16570 16540 16496 16469 16458>,
			<16755 16566 16538 16503 16478 16465>,
			<16756 16571 16535 16512 16488 16474>,
			<16756 16576 16530 16521 16497 16484>,
			<16757 16583 16520 16531 16506 16496>,
			<16761 16591 16517 16534 16509 16500>,
			<16766 16605 16525 16529 16506 16494>,
			<16771 16628 16539 16521 16500 16485>,
			<16777 16648 16555 16513 16487 16473>,
			<16785 16670 16574 16506 16467 16459>,
			<16795 16685 16586 16504 16461 16452>,
			<16807 16686 16594 16506 16460 16450>,
			<16820 16687 16596 16504 16459 16448>,
			<16835 16685 16595 16498 16457 16446>,
			<16854 16683 16572 16493 16460 16448>,
			<16856 16673 16554 16466 16439 16433>,
			<16791 16671 16582 16482 16443 16437>,
			<16793 16680 16599 16500 16453 16445>,
			<16815 16692 16625 16524 16464 16450>,
			<16886 16712 16667 16554 16476 16457>,
			<17001 16760 16724 16566 16485 16473>,
			<17222 16971 16799 16548 16479 16467>,
			<17746 17770 17011 16545 16453 16442>,
			<19521 26179 20590 16588 16459 16449>,
			<31557 65535 65535 16698 16484 16473>,
			<31557 65535 65535 16698 16484 16473>,
			<31557 65535 65535 16698 16484 16473>;
	};

	qcom,pc-temp-y5-lut {
		qcom,lut-col-legend = <(-10) 0 10 25 40 50>;
		qcom,lut-row-legend = <10000 9800 9600 9400 9200 9000>,
			<8800 8600 8400 8200 8000 7800>,
			<7600 7400 7200 7000 6800 6600>,
			<6400 6200 6000 5800 5600 5400>,
			<5200 5000 4800 4600 4400 4200>,
			<4000 3800 3600 3400 3200 3000>,
			<2800 2600 2400 2200 2000 1800>,
			<1600 1400 1200 1000 900 800>,
			<700 600 500 400 300 200>,
			<100 0>;
		qcom,lut-data = <10610 13429 16438 19415 19269 17988>,
			<11873 14176 17729 19188 19351 18164>,
			<13094 15112 18578 18885 19440 18347>,
			<14226 16057 19072 18515 19513 18500>,
			<15220 16833 19299 18089 19548 18592>,
			<16027 17259 19336 17616 19521 18588>,
			<16667 17461 19008 17066 19456 18520>,
			<17194 17586 18514 16485 19358 18404>,
			<17615 17629 18105 15841 19108 18092>,
			<17960 17639 17709 15195 18588 17518>,
			<18266 17680 17511 15063 17994 17207>,
			<18562 17950 17404 15360 17270 17489>,
			<18840 18384 17355 15586 16502 17766>,
			<19093 18920 17534 15347 15624 17792>,
			<19350 19621 18014 14945 14833 17742>,
			<19531 20169 18782 14953 14727 17210>,
			<19647 20624 20281 15467 14878 16057>,
			<19734 20909 21526 16298 14963 15402>,
			<19166 20972 22370 18583 14802 15294>,
			<16193 21006 22923 21265 14600 15242>,
			<14283 21081 22892 22642 15587 15602>,
			<15622 21282 22637 23615 18830 16956>,
			<17599 21413 22538 23776 20469 18417>,
			<17656 21337 22441 22647 20889 20257>,
			<16147 21202 22345 21530 21079 21471>,
			<14696 21279 22153 21135 20890 20639>,
			<13684 21972 21827 20821 20371 18842>,
			<12904 22533 21894 20924 19811 18296>,
			<12760 21844 22269 21819 18947 18211>,
			<12746 20433 22666 22619 18479 18160>,
			<12734 19374 23432 22997 18735 18046>,
			<12785 17582 24255 23303 19274 17912>,
			<12887 16833 24279 23662 19884 17969>,
			<12928 17171 23995 24069 20697 18327>,
			<12980 17692 23721 24276 21532 18839>,
			<13001 17922 23448 24622 22536 20131>,
			<13000 17655 23211 24900 23239 21351>,
			<13013 17291 23157 24808 23087 21505>,
			<13030 15996 23217 24583 22506 21431>,
			<13070 14938 23101 24205 21856 21492>,
			<13101 14891 22654 23432 20940 21780>,
			<13184 14746 22369 22697 20604 21668>,
			<13298 14260 22196 22200 20643 20405>,
			<13341 13935 21381 22521 19176 18744>,
			<13600 13517 16469 19626 21091 21525>,
			<13660 13567 14581 21074 20124 20093>,
			<13637 13510 14506 19031 19882 18590>,
			<13530 13723 14517 18363 17944 19564>,
			<12967 13738 14283 18102 17170 19457>,
			<12420 13502 14325 18546 19509 19923>,
			<11602 12237 14357 19763 20910 21426>,
			<10543 10451 13173 20890 22817 24047>,
			<9656 9148 10136 20881 24694 27981>,
			<9041 8770 8984 20525 26681 27228>,
			<9041 8770 8984 20525 26681 27228>,
			<9041 8770 8984 20525 26681 27228>;
	};

	qcom,pc-temp-y6-lut {
		qcom,lut-col-legend = <(-10) 0 10 25 40 50>;
		qcom,lut-row-legend = <10000 9800 9600 9400 9200 9000>,
			<8800 8600 8400 8200 8000 7800>,
			<7600 7400 7200 7000 6800 6600>,
			<6400 6200 6000 5800 5600 5400>,
			<5200 5000 4800 4600 4400 4200>,
			<4000 3800 3600 3400 3200 3000>,
			<2800 2600 2400 2200 2000 1800>,
			<1600 1400 1200 1000 900 800>,
			<700 600 500 400 300 200>,
			<100 0>;
		qcom,lut-data = <5939 5440 5175 5031 4973 4959>,
			<5959 5452 5187 5032 4972 4958>,
			<5975 5464 5196 5033 4972 4958>,
			<5986 5475 5202 5034 4972 4958>,
			<5993 5482 5205 5035 4972 4958>,
			<5995 5485 5206 5036 4972 4958>,
			<5992 5483 5203 5037 4973 4959>,
			<5985 5479 5199 5038 4974 4959>,
			<5978 5475 5197 5039 4976 4960>,
			<5969 5470 5195 5040 4977 4962>,
			<5959 5465 5194 5042 4978 4963>,
			<5950 5463 5195 5045 4980 4965>,
			<5941 5460 5195 5048 4982 4966>,
			<5932 5457 5196 5052 4984 4968>,
			<5922 5453 5198 5056 4986 4970>,
			<5912 5448 5199 5060 4989 4972>,
			<5900 5439 5201 5066 4992 4974>,
			<5887 5429 5201 5071 4996 4976>,
			<5871 5418 5194 5079 5000 4979>,
			<5851 5406 5182 5084 5005 4983>,
			<5840 5397 5171 5079 5010 4988>,
			<5841 5390 5160 5060 5014 4994>,
			<5842 5385 5152 5045 5014 4995>,
			<5840 5380 5146 5033 4993 4978>,
			<5832 5376 5142 5027 4974 4962>,
			<5827 5375 5140 5026 4972 4960>,
			<5832 5374 5139 5026 4971 4958>,
			<5843 5373 5139 5026 4971 4958>,
			<5858 5371 5140 5028 4973 4960>,
			<5881 5368 5141 5031 4975 4962>,
			<5907 5370 5142 5034 4978 4965>,
			<5933 5381 5143 5037 4981 4967>,
			<5961 5395 5143 5040 4984 4970>,
			<5991 5413 5143 5043 4988 4974>,
			<6025 5434 5144 5044 4989 4975>,
			<6062 5459 5151 5043 4988 4974>,
			<6103 5486 5161 5041 4987 4971>,
			<6148 5517 5172 5040 4983 4968>,
			<6198 5551 5186 5038 4976 4963>,
			<6253 5589 5201 5038 4974 4961>,
			<6312 5633 5216 5040 4974 4961>,
			<6372 5683 5233 5041 4974 4961>,
			<6437 5742 5253 5041 4974 4960>,
			<6506 5817 5267 5041 4975 4961>,
			<6591 5883 5269 5031 4968 4955>,
			<6627 6004 5336 5043 4970 4958>,
			<6701 6104 5385 5050 4975 4962>,
			<6855 6242 5453 5063 4979 4966>,
			<7165 6430 5549 5077 4985 4970>,
			<7679 6766 5698 5086 4991 4975>,
			<8642 7688 5963 5087 4989 4973>,
			<10747 10515 6673 5099 4980 4965>,
			<16788 24290 10349 5138 4984 4970>,
			<41635 65535 37438 5236 4995 4978>,
			<41635 65535 37438 5236 4995 4978>,
			<41635 65535 37438 5236 4995 4978>;
	};
};
